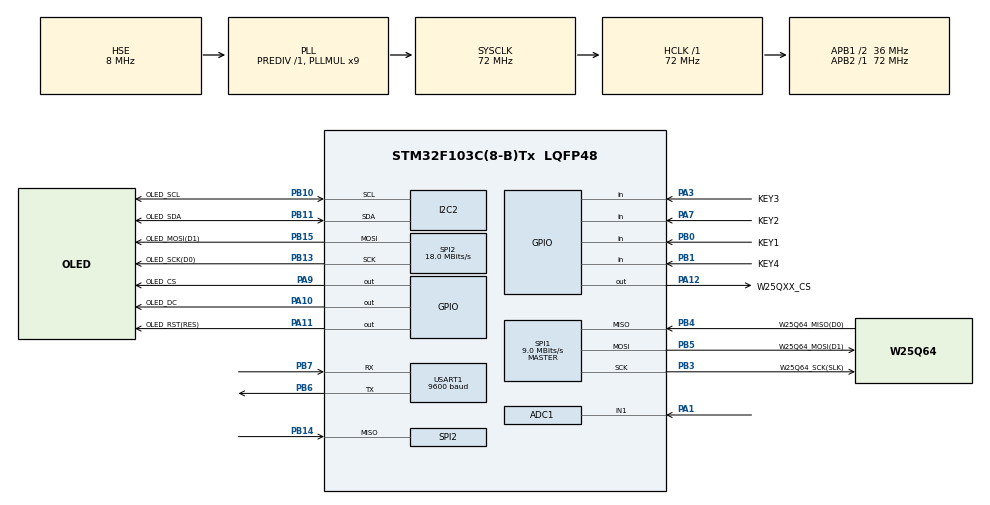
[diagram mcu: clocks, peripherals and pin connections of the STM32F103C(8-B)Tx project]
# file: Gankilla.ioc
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ADC1.Channel-6\#ChannelRegularConversion=ADC_CHANNEL_1
ADC1.NbrOfConversionFlag=1
ADC1.Rank-6\#ChannelRegularConversion=1
ADC1.SamplingTime-6\#ChannelRegularConversion=ADC_SAMPLETIME_1CYCLE_5
ADC1.master=1
Dma.Request0=SPI2_TX
Dma.SPI2_TX.0.Direction=DMA_MEMORY_TO_PERIPH
Dma.SPI2_TX.0.Instance=DMA1_Channel5
Dma.SPI2_TX.0.MemDataAlignment=DMA_MDATAALIGN_BYTE
Dma.SPI2_TX.0.MemInc=DMA_MINC_ENABLE
Dma.SPI2_TX.0.Mode=DMA_NORMAL
Dma.SPI2_TX.0.PeriphDataAlignment=DMA_PDATAALIGN_BYTE
Dma.SPI2_TX.0.PeriphInc=DMA_PINC_DISABLE
Dma.SPI2_TX.0.Priority=DMA_PRIORITY_LOW
Mcu.Family=STM32F1
Mcu.Name=STM32F103C(8-B)Tx
Mcu.Package=LQFP48
NVIC.DMA1_Channel5_IRQn=true\:0\:0\:false\:false\:true\:false\:true\:true
NVIC.PriorityGroup=NVIC_PRIORITYGROUP_4
NVIC.TIM2_IRQn=true\:0\:0\:false\:false\:true\:true\:true\:true
PA1.Signal=ADCx_IN1
PA10.GPIO_Label=OLED_DC
PA10.Signal=GPIO_Output
PA11.GPIO_Label=OLED_RST(RES)
PA11.Signal=GPIO_Output
PA12.GPIO_Label=W25QXX_CS
PA12.Signal=GPIO_Output
PA13.Mode=Serial_Wire
PA13.Signal=SYS_JTMS-SWDIO
PA14.Mode=Serial_Wire
PA14.Signal=SYS_JTCK-SWCLK
PA3.GPIO_Label=KEY3
PA3.GPIO_PuPd=GPIO_PULLUP
PA3.Signal=GPIO_Input
PA7.GPIO_Label=KEY2
PA7.GPIO_PuPd=GPIO_PULLUP
PA7.Signal=GPIO_Input
PA9.GPIO_Label=OLED_CS
PA9.Signal=GPIO_Output
PB0.GPIO_Label=KEY1
PB0.GPIO_PuPd=GPIO_PULLUP
PB0.Signal=GPIO_Input
PB1.GPIO_Label=KEY4
PB1.GPIO_PuPd=GPIO_PULLUP
PB1.Signal=GPIO_Input
PB10.GPIO_Label=OLED_SCL
PB10.Mode=I2C
PB10.Signal=I2C2_SCL
PB11.GPIO_Label=OLED_SDA
PB11.Mode=I2C
PB11.Signal=I2C2_SDA
PB13.GPIO_Label=OLED_SCK(D0)
PB13.Mode=Full_Duplex_Master
PB13.Signal=SPI2_SCK
PB14.Mode=Full_Duplex_Master
PB14.Signal=SPI2_MISO
PB15.GPIO_Label=OLED_MOSI(D1)
PB15.Mode=Full_Duplex_Master
PB15.Signal=SPI2_MOSI
PB3.GPIO_Label=W25Q64_SCK(SLK)
PB3.GPIO_Mode=GPIO_MODE_AF_PP
PB3.GPIO_Speed=GPIO_SPEED_FREQ_HIGH
PB3.Mode=Full_Duplex_Master
PB3.Signal=SPI1_SCK
PB4.GPIO_Label=W25Q64_MISO(D0)
PB4.GPIO_Mode=GPIO_MODE_INPUT
PB4.GPIO_PuPd=GPIO_NOPULL
PB4.Mode=Full_Duplex_Master
PB4.Signal=SPI1_MISO
PB5.GPIO_Label=W25Q64_MOSI(D1)
PB5.GPIO_Mode=GPIO_MODE_AF_PP
PB5.GPIO_Speed=GPIO_SPEED_FREQ_HIGH
PB5.Mode=Full_Duplex_Master
PB5.Signal=SPI1_MOSI
PB6.Mode=Asynchronous
PB6.Signal=USART1_TX
PB7.Mode=Asynchronous
PB7.Signal=USART1_RX
PD0-OSC_IN.Mode=HSE-External-Oscillator
PD0-OSC_IN.Signal=RCC_OSC_IN
PD1-OSC_OUT.Mode=HSE-External-Oscillator
PD1-OSC_OUT.Signal=RCC_OSC_OUT
ProjectManager.HeapSize=0x200
ProjectManager.StackSize=0x400
ProjectManager.TargetToolchain=STM32CubeIDE
RCC.ADCPresc=RCC_ADCPCLK2_DIV6
RCC.AHBFreq_Value=72000000
RCC.APB1CLKDivider=RCC_HCLK_DIV2
RCC.APB1Freq_Value=36000000
RCC.APB1TimFreq_Value=72000000
RCC.APB2Freq_Value=72000000
RCC.APB2TimFreq_Value=72000000
RCC.HCLKFreq_Value=72000000
RCC.PLLMUL=RCC_PLL_MUL9
RCC.PLLSourceVirtual=RCC_PLLSOURCE_HSE
RCC.SYSCLKFreq_VALUE=72000000
RCC.SYSCLKSource=RCC_SYSCLKSOURCE_PLLCLK
RCC.USBFreq_Value=72000000
SH.ADCx_IN1.0=ADC1_IN1,IN1
SPI1.BaudRatePrescaler=SPI_BAUDRATEPRESCALER_8
SPI1.CalculateBaudRate=9.0 MBits/s
SPI1.Direction=SPI_DIRECTION_2LINES
SPI1.Mode=SPI_MODE_MASTER
SPI1.VirtualType=VM_MASTER
SPI2.CRCCalculation=SPI_CRCCALCULATION_DISABLE
SPI2.CalculateBaudRate=18.0 MBits/s
SPI2.Direction=SPI_DIRECTION_2LINES
SPI2.Mode=SPI_MODE_MASTER
SPI2.VirtualType=VM_MASTER
TIM2.Period=5000
TIM2.Prescaler=72-1
USART1.BaudRate=9600
USART1.VirtualMode=VM_ASYNC
VP_TIM2_VS_ClockSourceINT.Mode=Internal
board=custom

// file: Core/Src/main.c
/* USER CODE BEGIN Header */
/**
  ******************************************************************************
  * @file           : main.c
  * @brief          : Main program body
  ******************************************************************************
  * @attention
  *
  * Copyright (c) 2024 STMicroelectronics.
  * All rights reserved.
  *
  * This software is licensed under terms that can be found in the LICENSE file
  * in the root directory of this software component.
  * If no LICENSE file comes with this software, it is provided AS-IS.
  *
  ******************************************************************************
  */
/* USER CODE END Header */
#include "main.h"

/* USER CODE BEGIN Includes */
#include "stdarg.h"
#include "app/astra.h"
/* USER CODE END Includes */

ADC_HandleTypeDef hadc1;

I2C_HandleTypeDef hi2c2;

SPI_HandleTypeDef hspi1;
SPI_HandleTypeDef hspi2;
DMA_HandleTypeDef hdma_spi2_tx;

TIM_HandleTypeDef htim2;

UART_HandleTypeDef huart1;

void SystemClock_Config(void);
static void MX_GPIO_Init(void);
static void MX_DMA_Init(void);
static void MX_SPI2_Init(void);
static void MX_ADC1_Init(void);
static void MX_TIM2_Init(void);
static void MX_USART1_UART_Init(void);
static void MX_SPI1_Init(void);
static void MX_I2C2_Init(void);

int main(void)
{

  /* MCU Configuration--------------------------------------------------------*/

  /* Reset of all peripherals, Initializes the Flash interface and the Systick. */
  HAL_Init();

  /* Configure the system clock */
  SystemClock_Config();

  /* Initialize all configured peripherals */
  MX_GPIO_Init();
  MX_DMA_Init();
  MX_SPI2_Init();
  MX_ADC1_Init();
  MX_TIM2_Init();
  MX_USART1_UART_Init();
  MX_SPI1_Init();
  MX_I2C2_Init();
  /* USER CODE BEGIN 2 */
  astraCoreInit();
  /* USER CODE END 2 */

  /* Infinite loop */
  /* USER CODE BEGIN WHILE */
  while (1)
  {
    astraCoreUpdate();
    /* USER CODE END WHILE */

  }
}

void SystemClock_Config(void)
{
  RCC_OscInitTypeDef RCC_OscInitStruct = {0};
  RCC_ClkInitTypeDef RCC_ClkInitStruct = {0};
  RCC_PeriphCLKInitTypeDef PeriphClkInit = {0};

  /** Initializes the RCC Oscillators according to the specified parameters
  * in the RCC_OscInitTypeDef structure.
  */
  RCC_OscInitStruct.OscillatorType = RCC_OSCILLATORTYPE_HSE;
  RCC_OscInitStruct.HSEState = RCC_HSE_ON;
  RCC_OscInitStruct.HSEPredivValue = RCC_HSE_PREDIV_DIV1;
  RCC_OscInitStruct.HSIState = RCC_HSI_ON;
  RCC_OscInitStruct.PLL.PLLState = RCC_PLL_ON;
  RCC_OscInitStruct.PLL.PLLSource = RCC_PLLSOURCE_HSE;
  RCC_OscInitStruct.PLL.PLLMUL = RCC_PLL_MUL9;
  if (HAL_RCC_OscConfig(&RCC_OscInitStruct) != HAL_OK)
  {
    Error_Handler();
  }

  /** Initializes the CPU, AHB and APB buses clocks
  */
  RCC_ClkInitStruct.ClockType = RCC_CLOCKTYPE_HCLK|RCC_CLOCKTYPE_SYSCLK
                              |RCC_CLOCKTYPE_PCLK1|RCC_CLOCKTYPE_PCLK2;
  RCC_ClkInitStruct.SYSCLKSource = RCC_SYSCLKSOURCE_PLLCLK;
  RCC_ClkInitStruct.AHBCLKDivider = RCC_SYSCLK_DIV1;
  RCC_ClkInitStruct.APB1CLKDivider = RCC_HCLK_DIV2;
  RCC_ClkInitStruct.APB2CLKDivider = RCC_HCLK_DIV1;

  if (HAL_RCC_ClockConfig(&RCC_ClkInitStruct, FLASH_LATENCY_2) != HAL_OK)
  {
    Error_Handler();
  }
  PeriphClkInit.PeriphClockSelection = RCC_PERIPHCLK_ADC;
  PeriphClkInit.AdcClockSelection = RCC_ADCPCLK2_DIV6;
  if (HAL_RCCEx_PeriphCLKConfig(&PeriphClkInit) != HAL_OK)
  {
    Error_Handler();
  }
}

static void MX_ADC1_Init(void)
{

  ADC_ChannelConfTypeDef sConfig = {0};

  /** Common config
  */
  hadc1.Instance = ADC1;
  hadc1.Init.ScanConvMode = ADC_SCAN_DISABLE;
  hadc1.Init.ContinuousConvMode = DISABLE;
  hadc1.Init.DiscontinuousConvMode = DISABLE;
  hadc1.Init.ExternalTrigConv = ADC_SOFTWARE_START;
  hadc1.Init.DataAlign = ADC_DATAALIGN_RIGHT;
  hadc1.Init.NbrOfConversion = 1;
  if (HAL_ADC_Init(&hadc1) != HAL_OK)
  {
    Error_Handler();
  }

  /** Configure Regular Channel
  */
  sConfig.Channel = ADC_CHANNEL_1;
  sConfig.Rank = ADC_REGULAR_RANK_1;
  sConfig.SamplingTime = ADC_SAMPLETIME_1CYCLE_5;
  if (HAL_ADC_ConfigChannel(&hadc1, &sConfig) != HAL_OK)
  {
    Error_Handler();
  }

}

static void MX_I2C2_Init(void)
{

  hi2c2.Instance = I2C2;
  hi2c2.Init.ClockSpeed = 100000;
  hi2c2.Init.DutyCycle = I2C_DUTYCYCLE_2;
  hi2c2.Init.OwnAddress1 = 0;
  hi2c2.Init.AddressingMode = I2C_ADDRESSINGMODE_7BIT;
  hi2c2.Init.DualAddressMode = I2C_DUALADDRESS_DISABLE;
  hi2c2.Init.OwnAddress2 = 0;
  hi2c2.Init.GeneralCallMode = I2C_GENERALCALL_DISABLE;
  hi2c2.Init.NoStretchMode = I2C_NOSTRETCH_DISABLE;
  if (HAL_I2C_Init(&hi2c2) != HAL_OK)
  {
    Error_Handler();
  }

}

static void MX_SPI1_Init(void)
{

  /* SPI1 parameter configuration*/
  hspi1.Instance = SPI1;
  hspi1.Init.Mode = SPI_MODE_MASTER;
  hspi1.Init.Direction = SPI_DIRECTION_2LINES;
  hspi1.Init.DataSize = SPI_DATASIZE_8BIT;
  hspi1.Init.CLKPolarity = SPI_POLARITY_LOW;
  hspi1.Init.CLKPhase = SPI_PHASE_1EDGE;
  hspi1.Init.NSS = SPI_NSS_SOFT;
  hspi1.Init.BaudRatePrescaler = SPI_BAUDRATEPRESCALER_8;
  hspi1.Init.FirstBit = SPI_FIRSTBIT_MSB;
  hspi1.Init.TIMode = SPI_TIMODE_DISABLE;
  hspi1.Init.CRCCalculation = SPI_CRCCALCULATION_DISABLE;
  hspi1.Init.CRCPolynomial = 10;
  if (HAL_SPI_Init(&hspi1) != HAL_OK)
  {
    Error_Handler();
  }

}

static void MX_SPI2_Init(void)
{

  /* SPI2 parameter configuration*/
  hspi2.Instance = SPI2;
  hspi2.Init.Mode = SPI_MODE_MASTER;
  hspi2.Init.Direction = SPI_DIRECTION_2LINES;
  hspi2.Init.DataSize = SPI_DATASIZE_8BIT;
  hspi2.Init.CLKPolarity = SPI_POLARITY_LOW;
  hspi2.Init.CLKPhase = SPI_PHASE_1EDGE;
  hspi2.Init.NSS = SPI_NSS_SOFT;
  hspi2.Init.BaudRatePrescaler = SPI_BAUDRATEPRESCALER_2;
  hspi2.Init.FirstBit = SPI_FIRSTBIT_MSB;
  hspi2.Init.TIMode = SPI_TIMODE_DISABLE;
  hspi2.Init.CRCCalculation = SPI_CRCCALCULATION_DISABLE;
  hspi2.Init.CRCPolynomial = 10;
  if (HAL_SPI_Init(&hspi2) != HAL_OK)
  {
    Error_Handler();
  }

}

static void MX_TIM2_Init(void)
{

  TIM_ClockConfigTypeDef sClockSourceConfig = {0};
  TIM_MasterConfigTypeDef sMasterConfig = {0};

  htim2.Instance = TIM2;
  htim2.Init.Prescaler = 72-1;
  htim2.Init.CounterMode = TIM_COUNTERMODE_UP;
  htim2.Init.Period = 5000;
  htim2.Init.ClockDivision = TIM_CLOCKDIVISION_DIV1;
  htim2.Init.AutoReloadPreload = TIM_AUTORELOAD_PRELOAD_DISABLE;
  if (HAL_TIM_Base_Init(&htim2) != HAL_OK)
  {
    Error_Handler();
  }
  sClockSourceConfig.ClockSource = TIM_CLOCKSOURCE_INTERNAL;
  if (HAL_TIM_ConfigClockSource(&htim2, &sClockSourceConfig) != HAL_OK)
  {
    Error_Handler();
  }
  sMasterConfig.MasterOutputTrigger = TIM_TRGO_RESET;
  sMasterConfig.MasterSlaveMode = TIM_MASTERSLAVEMODE_DISABLE;
  if (HAL_TIMEx_MasterConfigSynchronization(&htim2, &sMasterConfig) != HAL_OK)
  {
    Error_Handler();
  }

}

static void MX_USART1_UART_Init(void)
{

  huart1.Instance = USART1;
  huart1.Init.BaudRate = 9600;
  huart1.Init.WordLength = UART_WORDLENGTH_8B;
  huart1.Init.StopBits = UART_STOPBITS_1;
  huart1.Init.Parity = UART_PARITY_NONE;
  huart1.Init.Mode = UART_MODE_TX_RX;
  huart1.Init.HwFlowCtl = UART_HWCONTROL_NONE;
  huart1.Init.OverSampling = UART_OVERSAMPLING_16;
  if (HAL_UART_Init(&huart1) != HAL_OK)
  {
    Error_Handler();
  }

}

static void MX_DMA_Init(void)
{

  /* DMA controller clock enable */
  __HAL_RCC_DMA1_CLK_ENABLE();

  /* DMA interrupt init */
  /* DMA1_Channel5_IRQn interrupt configuration */
  HAL_NVIC_SetPriority(DMA1_Channel5_IRQn, 0, 0);
  HAL_NVIC_EnableIRQ(DMA1_Channel5_IRQn);

}

static void MX_GPIO_Init(void)
{
  GPIO_InitTypeDef GPIO_InitStruct = {0};

  /* GPIO Ports Clock Enable */
  __HAL_RCC_GPIOD_CLK_ENABLE();
  __HAL_RCC_GPIOA_CLK_ENABLE();
  __HAL_RCC_GPIOB_CLK_ENABLE();

  /*Configure GPIO pin Output Level */
  HAL_GPIO_WritePin(GPIOA, OLED_CS_Pin|OLED_DC_Pin|OLED_RST_Pin|W25QXX_CS_Pin, GPIO_PIN_RESET);

  /*Configure GPIO pins : KEY3_Pin KEY2_Pin */
  GPIO_InitStruct.Pin = KEY3_Pin|KEY2_Pin;
  GPIO_InitStruct.Mode = GPIO_MODE_INPUT;
  GPIO_InitStruct.Pull = GPIO_PULLUP;
  HAL_GPIO_Init(GPIOA, &GPIO_InitStruct);

  /*Configure GPIO pins : KEY1_Pin KEY4_Pin */
  GPIO_InitStruct.Pin = KEY1_Pin|KEY4_Pin;
  GPIO_InitStruct.Mode = GPIO_MODE_INPUT;
  GPIO_InitStruct.Pull = GPIO_PULLUP;
  HAL_GPIO_Init(GPIOB, &GPIO_InitStruct);

  /*Configure GPIO pins : OLED_CS_Pin OLED_DC_Pin OLED_RST_Pin W25QXX_CS_Pin */
  GPIO_InitStruct.Pin = OLED_CS_Pin|OLED_DC_Pin|OLED_RST_Pin|W25QXX_CS_Pin;
  GPIO_InitStruct.Mode = GPIO_MODE_OUTPUT_PP;
  GPIO_InitStruct.Pull = GPIO_NOPULL;
  GPIO_InitStruct.Speed = GPIO_SPEED_FREQ_LOW;
  HAL_GPIO_Init(GPIOA, &GPIO_InitStruct);

}

/* USER CODE BEGIN 4 */
void print(char* format, ...)
{
  uint8_t i;
  char chars[256];
  va_list args;
  va_start(args, format);
  vsprintf(chars, format, args);
  va_end(args);
  for (i=0;chars[i]!='\0';i++) {};
  HAL_UART_Transmit(&huart1, (uint8_t *) chars, i, HAL_MAX_DELAY);
}
/* USER CODE END 4 */

void Error_Handler(void)
{
  __disable_irq();
  while (1)
  {
  }
}
